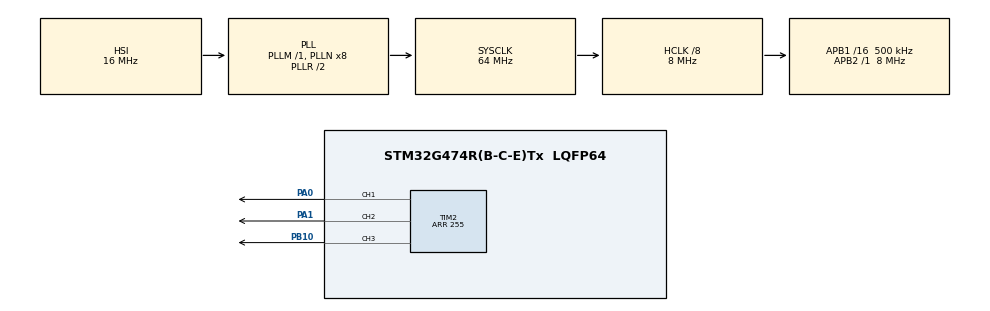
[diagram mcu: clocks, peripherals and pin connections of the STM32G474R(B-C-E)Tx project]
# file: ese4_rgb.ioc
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Mcu.Family=STM32G4
Mcu.Name=STM32G474R(B-C-E)Tx
Mcu.Package=LQFP64
NVIC.PriorityGroup=NVIC_PRIORITYGROUP_4
PA0.Signal=S_TIM2_CH1
PA1.Signal=S_TIM2_CH2
PB10.Signal=S_TIM2_CH3
ProjectManager.HeapSize=0x200
ProjectManager.StackSize=0x400
ProjectManager.TargetToolchain=STM32CubeIDE
RCC.ADC12Freq_Value=64000000
RCC.ADC345Freq_Value=64000000
RCC.AHBCLKDivider=RCC_SYSCLK_DIV8
RCC.AHBFreq_Value=8000000
RCC.APB1CLKDivider=RCC_HCLK_DIV16
RCC.APB1Freq_Value=500000
RCC.APB1TimFreq_Value=1000000
RCC.APB2Freq_Value=8000000
RCC.APB2TimFreq_Value=8000000
RCC.CortexFreq_Value=8000000
RCC.EXTERNAL_CLOCK_VALUE=12288000
RCC.HCLKFreq_Value=8000000
RCC.HSE_VALUE=24000000
RCC.HSI48_VALUE=48000000
RCC.HSI_VALUE=16000000
RCC.LSE_VALUE=32768
RCC.RTCClockSelection=RCC_RTCCLKSOURCE_LSE
RCC.SYSCLKFreq_VALUE=64000000
RCC.SYSCLKSource=RCC_SYSCLKSOURCE_PLLCLK
RCC.USBFreq_Value=64000000
RCC.VCOOutputFreq_Value=128000000
SH.S_TIM2_CH1.0=TIM2_CH1,PWM Generation1 CH1
SH.S_TIM2_CH2.0=TIM2_CH2,PWM Generation2 CH2
SH.S_TIM2_CH3.0=TIM2_CH3,PWM Generation3 CH3
TIM2.Channel-PWM\ Generation1\ CH1=TIM_CHANNEL_1
TIM2.Channel-PWM\ Generation2\ CH2=TIM_CHANNEL_2
TIM2.Channel-PWM\ Generation3\ CH3=TIM_CHANNEL_3
TIM2.PeriodNoDither=255
VP_SYS_VS_DBSignals.Mode=DisableDeadBatterySignals
board=NUCLEO-G474RE

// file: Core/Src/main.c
/* USER CODE BEGIN Header */
/**
  ******************************************************************************
  * @file           : main.c
  * @brief          : Main program body
  ******************************************************************************
  * @attention
  *
  * Copyright (c) 2026 STMicroelectronics.
  * All rights reserved.
  *
  * This software is licensed under terms that can be found in the LICENSE file
  * in the root directory of this software component.
  * If no LICENSE file comes with this software, it is provided AS-IS.
  *
  ******************************************************************************
  */
/* USER CODE END Header */
#include "main.h"
#include "tim.h"
#include "gpio.h"

void SystemClock_Config(void);
/* USER CODE BEGIN PFP */
void Set_RGB(uint8_t R, uint8_t G, uint8_t B) {
    __HAL_TIM_SET_COMPARE(&htim2, TIM_CHANNEL_1, R);
    __HAL_TIM_SET_COMPARE(&htim2, TIM_CHANNEL_2, G);
    __HAL_TIM_SET_COMPARE(&htim2, TIM_CHANNEL_3, B);
}

/* USER CODE END PFP */

int main(void)
{

  /* MCU Configuration--------------------------------------------------------*/

  /* Reset of all peripherals, Initializes the Flash interface and the Systick. */
  HAL_Init();

  /* Configure the system clock */
  SystemClock_Config();

  /* Initialize all configured peripherals */
  MX_GPIO_Init();
  MX_TIM2_Init();

  /* Infinite loop */
  while (1)
  {

    /* USER CODE BEGIN 3 */
	  // 1. Da ROSSO a GIALLO (Aumenta il Verde)
	      for (int i = 0; i <= 255; i++) {
	          Set_RGB(255, i, 0);
	          HAL_Delay(10); // Più è basso, più è veloce
	      }

	      // 2. Da GIALLO a VERDE (Diminuisce il Rosso)
	      for (int i = 255; i >= 0; i--) {
	          Set_RGB(i, 255, 0);
	          HAL_Delay(10);
	      }

	      // 3. Da VERDE a CIANO (Aumenta il Blu)
	      for (int i = 0; i <= 255; i++) {
	          Set_RGB(0, 255, i);
	          HAL_Delay(10);
	      }

	      // 4. Da CIANO a BLU (Diminuisce il Verde)
	      for (int i = 255; i >= 0; i--) {
	          Set_RGB(0, i, 255);
	          HAL_Delay(10);
	      }

	      // 5. Da BLU a MAGENTA (Aumenta il Rosso)
	      for (int i = 0; i <= 255; i++) {
	          Set_RGB(i, 0, 255);
	          HAL_Delay(10);
	      }

	      // 6. Da MAGENTA a ROSSO (Diminuisce il Blu)
	      for (int i = 255; i >= 0; i--) {
	          Set_RGB(255, 0, i);
	          HAL_Delay(10);
	      }
  }
  /* USER CODE END 3 */
}

void SystemClock_Config(void)
{
  RCC_OscInitTypeDef RCC_OscInitStruct = {0};
  RCC_ClkInitTypeDef RCC_ClkInitStruct = {0};

  /** Configure the main internal regulator output voltage
  */
  HAL_PWREx_ControlVoltageScaling(PWR_REGULATOR_VOLTAGE_SCALE1);

  /** Initializes the RCC Oscillators according to the specified parameters
  * in the RCC_OscInitTypeDef structure.
  */
  RCC_OscInitStruct.OscillatorType = RCC_OSCILLATORTYPE_HSI;
  RCC_OscInitStruct.HSIState = RCC_HSI_ON;
  RCC_OscInitStruct.HSICalibrationValue = RCC_HSICALIBRATION_DEFAULT;
  RCC_OscInitStruct.PLL.PLLState = RCC_PLL_ON;
  RCC_OscInitStruct.PLL.PLLSource = RCC_PLLSOURCE_HSI;
  RCC_OscInitStruct.PLL.PLLM = RCC_PLLM_DIV1;
  RCC_OscInitStruct.PLL.PLLN = 8;
  RCC_OscInitStruct.PLL.PLLP = RCC_PLLP_DIV2;
  RCC_OscInitStruct.PLL.PLLQ = RCC_PLLQ_DIV2;
  RCC_OscInitStruct.PLL.PLLR = RCC_PLLR_DIV2;
  if (HAL_RCC_OscConfig(&RCC_OscInitStruct) != HAL_OK)
  {
    Error_Handler();
  }

  /** Initializes the CPU, AHB and APB buses clocks
  */
  RCC_ClkInitStruct.ClockType = RCC_CLOCKTYPE_HCLK|RCC_CLOCKTYPE_SYSCLK
                              |RCC_CLOCKTYPE_PCLK1|RCC_CLOCKTYPE_PCLK2;
  RCC_ClkInitStruct.SYSCLKSource = RCC_SYSCLKSOURCE_PLLCLK;
  RCC_ClkInitStruct.AHBCLKDivider = RCC_SYSCLK_DIV8;
  RCC_ClkInitStruct.APB1CLKDivider = RCC_HCLK_DIV16;
  RCC_ClkInitStruct.APB2CLKDivider = RCC_HCLK_DIV1;

  if (HAL_RCC_ClockConfig(&RCC_ClkInitStruct, FLASH_LATENCY_0) != HAL_OK)
  {
    Error_Handler();
  }
}

void Error_Handler(void)
{
  __disable_irq();
  while (1)
  {
  }
}
